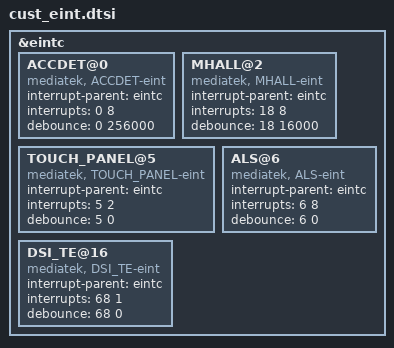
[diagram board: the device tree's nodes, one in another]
/*
 * Generated by MTK SP DrvGen Version 03.13.6 for MT6580. Copyright MediaTek Inc. (C) 2013.
 * Sun Jun 24 16:48:27 2018
 * Do Not Modify the File.
 */

/*************************
 * EINT DTSI File
*************************/

&eintc {
	ACCDET@0 {
		compatible = "mediatek, ACCDET-eint";
		interrupt-parent = <&eintc>;
		interrupts = <0 8>;
		debounce = <0 256000>;
	};

	MHALL@2 {
		compatible = "mediatek, MHALL-eint";
		interrupt-parent = <&eintc>;
		interrupts = <18 8>;
		debounce = <18 16000>;
	};

	TOUCH_PANEL@5 {
		compatible = "mediatek, TOUCH_PANEL-eint";
		interrupt-parent = <&eintc>;
		interrupts = <5 2>;
		debounce = <5 0>;
	};

	ALS@6 {
		compatible = "mediatek, ALS-eint";
		interrupt-parent = <&eintc>;
		interrupts = <6 8>;
		debounce = <6 0>;
	};

	DSI_TE@16 {
		compatible = "mediatek, DSI_TE-eint";
		interrupt-parent = <&eintc>;
		interrupts = <68 1>;
		debounce = <68 0>;
	};

};
